# XHSC_HC32L021 register map
Vendor: XHSC Co.Ltd; Series: ARMCM4; File version: 1.2
CPU: CM4 r0p0, little endian, no MPU, no FPU, 3 interrupt priority bits
Registers are 32-bit, read-write, reset 0x0 unless marked. A register's access mark holds for its fields unless they carry their own. Offsets are from the block's base; [hi:lo] are bit positions; {n}, {i} and the like mark numbered series.

## GTIM0 — desc GTIM
Base 0x40001800; alternate view of BTIM0
Same registers: GTIM1 0x40001C00 (alternate view of BTIM3)
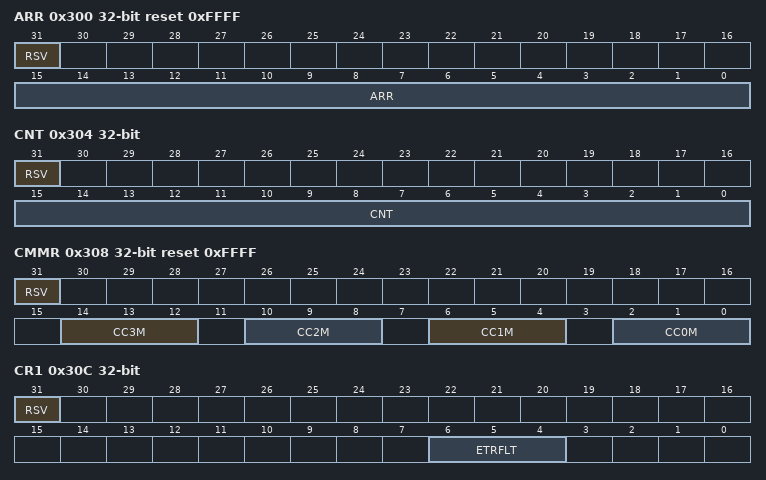
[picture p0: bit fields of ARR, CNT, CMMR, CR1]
0x300 ARR reset 0xFFFF (reset mask 0xFFFF)
  [31] RSV, [15:0] ARR
0x304 CNT (reset mask 0xFFFF)
  [31] RSV, [15:0] CNT
0x308 CMMR reset 0xFFFF (reset mask 0x7777)
  [31] RSV, [4n+2:4n] CC{n}M (n=0..3)
0x30C CR1 (reset mask 0x70)
  [31] RSV, [6:4] ETRFLT
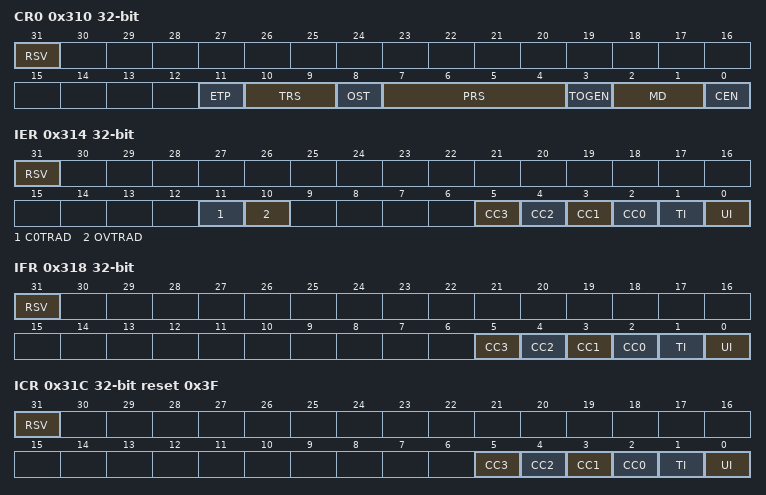
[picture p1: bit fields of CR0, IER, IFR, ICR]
0x310 CR0 (reset mask 0xFFF)
  [31] RSV, [11] ETP, [10:9] TRS, [8] OST, [7:4] PRS, [3] TOGEN, [2:1] MD, [0] CEN
0x314 IER (reset mask 0xFFF)
  [31] RSV, [11] C0TRAD, [10] OVTRAD, [n+2] CC{n} (n=0..3), [1] TI, [0] UI
0x318 IFR (reset mask 0x3F)
  [31] RSV, [n+2] CC{n} (n=0..3), [1] TI, [0] UI
0x31C ICR reset 0x3F (reset mask 0x3F)
  [31] RSV, [n+2] CC{n} (n=0..3), [1] TI, [0] UI
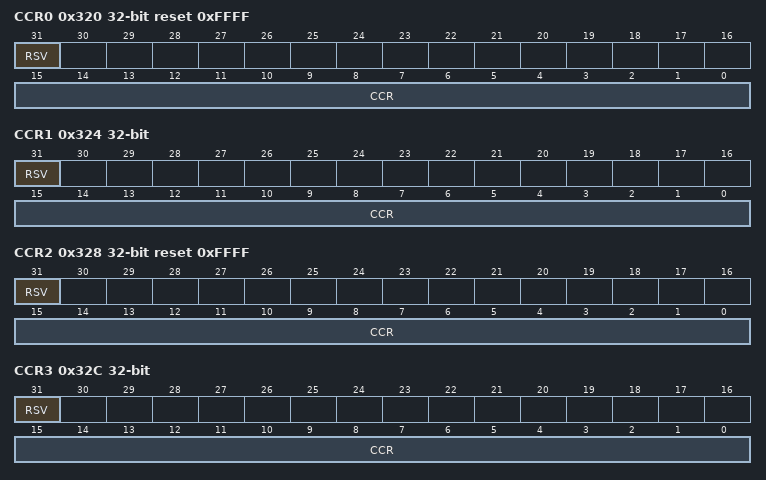
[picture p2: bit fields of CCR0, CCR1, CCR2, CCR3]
0x320 CCR0 reset 0xFFFF (reset mask 0xFFFF)
  [31] RSV, [15:0] CCR
0x324 CCR1 (reset mask 0xFFFF)
  [31] RSV, [15:0] CCR
0x328 CCR2 reset 0xFFFF (reset mask 0xFFFF)
  [31] RSV, [15:0] CCR
0x32C CCR3 (reset mask 0xFFFF)
  [31] RSV, [15:0] CCR

## HSI2C0 — desc HSI2C
Base 0x4000BC00
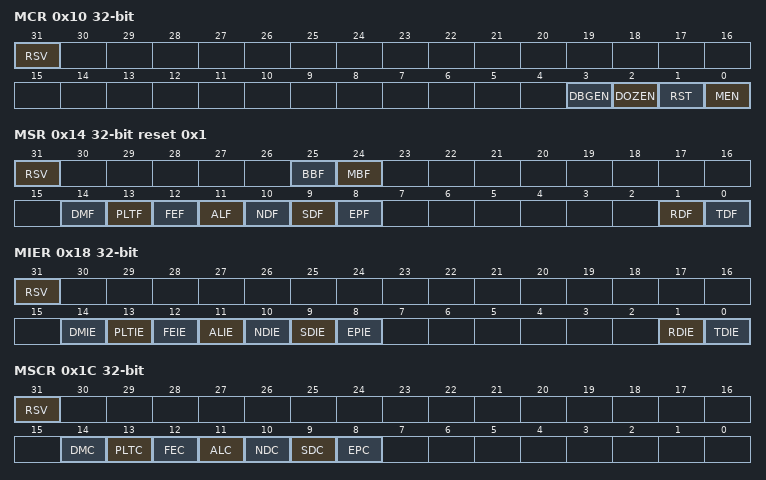
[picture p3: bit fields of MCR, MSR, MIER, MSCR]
0x10 MCR (reset mask 0xF)
  [31] RSV, [3] DBGEN, [2] DOZEN, [1] RST, [0] MEN
0x14 MSR ro reset 0x1 (reset mask 0x0)
  [31] RSV rw, [25] BBF, [24] MBF, [14] DMF, [13] PLTF, [12] FEF, [11] ALF, [10] NDF, [9] SDF, [8] EPF, [1] RDF, [0] TDF
0x18 MIER (reset mask 0x7F03)
  [31] RSV, [14] DMIE, [13] PLTIE, [12] FEIE, [11] ALIE, [10] NDIE, [9] SDIE, [8] EPIE, [1] RDIE, [0] TDIE
0x1C MSCR wo (reset mask 0x7F00)
  [31] RSV, [14] DMC, [13] PLTC, [12] FEC, [11] ALC, [10] NDC, [9] SDC, [8] EPC
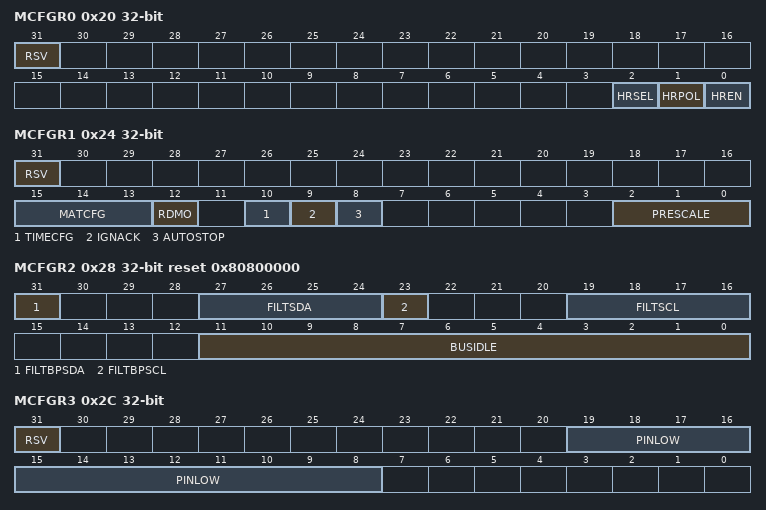
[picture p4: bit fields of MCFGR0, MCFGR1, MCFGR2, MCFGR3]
0x20 MCFGR0 (reset mask 0x307)
  [31] RSV, [2] HRSEL, [1] HRPOL, [0] HREN
0x24 MCFGR1 (reset mask 0xF707)
  [31] RSV, [15:13] MATCFG, [12] RDMO, [10] TIMECFG, [9] IGNACK, [8] AUTOSTOP, [2:0] PRESCALE
0x28 MCFGR2 reset 0x80800000
  [31] FILTBPSDA, [27:24] FILTSDA, [23] FILTBPSCL, [19:16] FILTSCL, [11:0] BUSIDLE
0x2C MCFGR3 (reset mask 0xFFF00)
  [31] RSV, [19:8] PINLOW
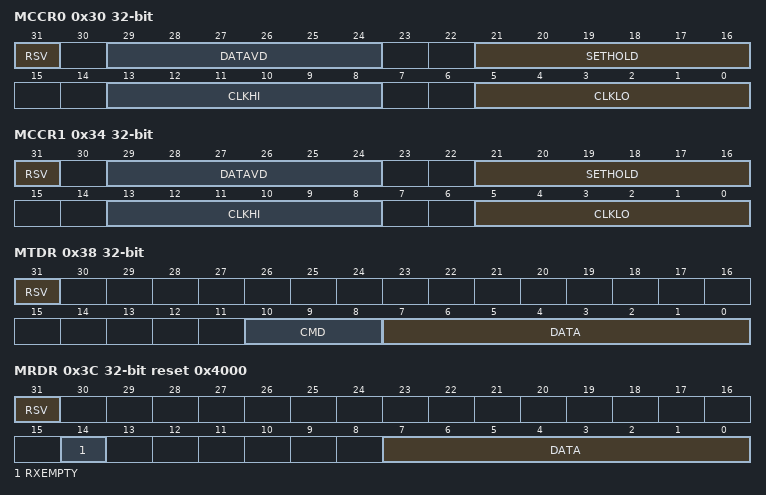
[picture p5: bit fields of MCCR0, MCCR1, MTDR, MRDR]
0x30 MCCR0 (reset mask 0x3F3F3F3F)
  [31] RSV, [29:24] DATAVD, [21:16] SETHOLD, [13:8] CLKHI, [5:0] CLKLO
0x34 MCCR1 (reset mask 0x3F3F3F3F)
  [31] RSV, [29:24] DATAVD, [21:16] SETHOLD, [13:8] CLKHI, [5:0] CLKLO
0x38 MTDR wo reset not defined
  [31] RSV, [10:8] CMD, [7:0] DATA
0x3C MRDR ro reset 0x4000 (reset mask 0x0)
  [31] RSV, [14] RXEMPTY, [7:0] DATA
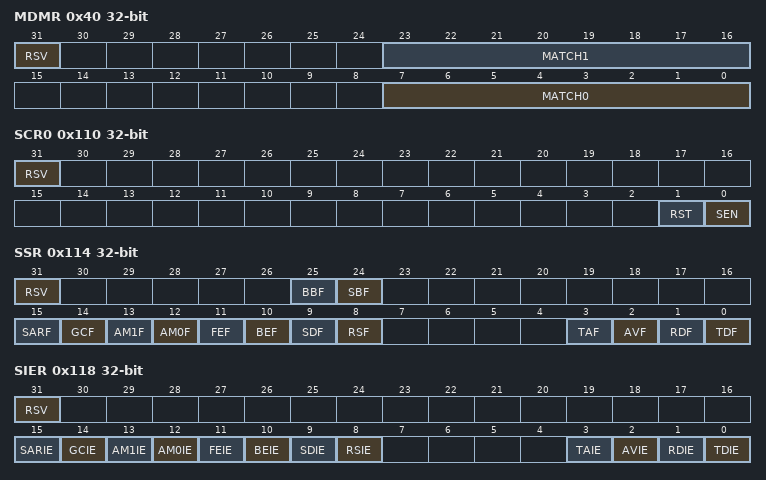
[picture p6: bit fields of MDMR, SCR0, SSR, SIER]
0x40 MDMR (reset mask 0xFF00FF)
  [31] RSV, [23:16] MATCH1, [7:0] MATCH0
0x110 SCR0 (reset mask 0x3)
  [31] RSV ro, [1] RST, [0] SEN
0x114 SSR ro reset not defined
  [31] RSV, [25] BBF, [24] SBF, [15] SARF, [14] GCF, [13] AM1F, [12] AM0F, [11] FEF, [10] BEF, [9] SDF, [8] RSF, [3] TAF, [2] AVF, [1] RDF, [0] TDF
0x118 SIER (reset mask 0xFF0F)
  [31] RSV, [15] SARIE, [14] GCIE, [13] AM1IE, [12] AM0IE, [11] FEIE, [10] BEIE, [9] SDIE, [8] RSIE, [3] TAIE, [2] AVIE, [1] RDIE, [0] TDIE
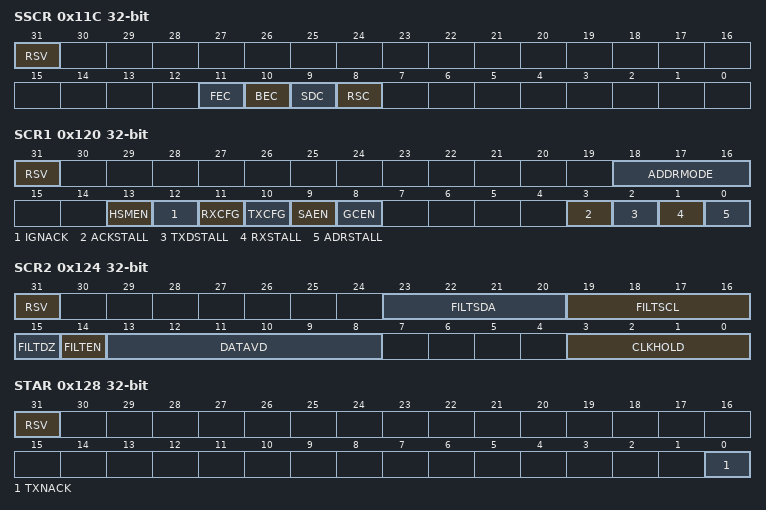
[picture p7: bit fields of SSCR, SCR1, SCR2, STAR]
0x11C SSCR wo reset not defined
  [31] RSV, [11] FEC, [10] BEC, [9] SDC, [8] RSC
0x120 SCR1 (reset mask 0x73F0F)
  [31] RSV, [18:16] ADDRMODE, [13] HSMEN, [12] IGNACK, [11] RXCFG, [10] TXCFG, [9] SAEN, [8] GCEN, [3] ACKSTALL, [2] TXDSTALL, [1] RXSTALL, [0] ADRSTALL
0x124 SCR2 (reset mask 0xFFFF0F)
  [31] RSV, [23:20] FILTSDA, [19:16] FILTSCL, [15] FILTDZ, [14] FILTEN, [13:8] DATAVD, [3:0] CLKHOLD
0x128 STAR (reset mask 0x1)
  [31] RSV, [0] TXNACK
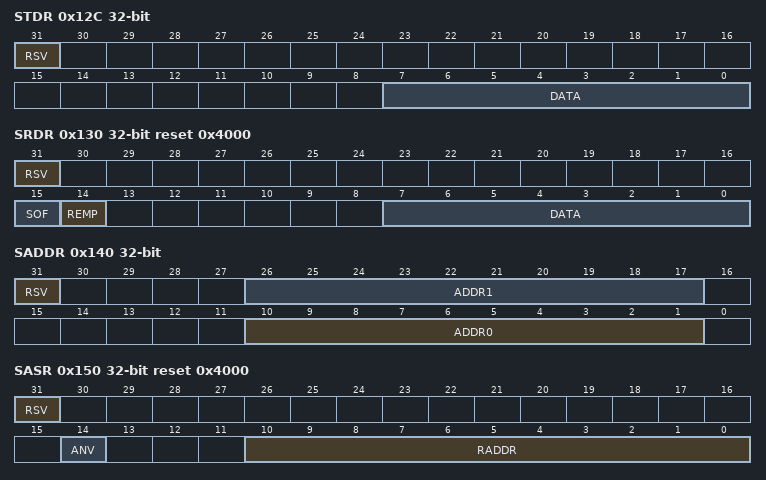
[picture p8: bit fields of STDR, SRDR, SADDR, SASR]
0x12C STDR wo reset not defined
  [31] RSV, [7:0] DATA
0x130 SRDR ro reset 0x4000 (reset mask 0x0)
  [31] RSV, [15] SOF, [14] REMP, [7:0] DATA
0x140 SADDR (reset mask 0x7FE07FE)
  [31] RSV, [26:17] ADDR1, [10:1] ADDR0
0x150 SASR ro reset 0x4000 (reset mask 0x0)
  [31] RSV, [14] ANV, [10:0] RADDR

## IWDT
Base 0x40001000
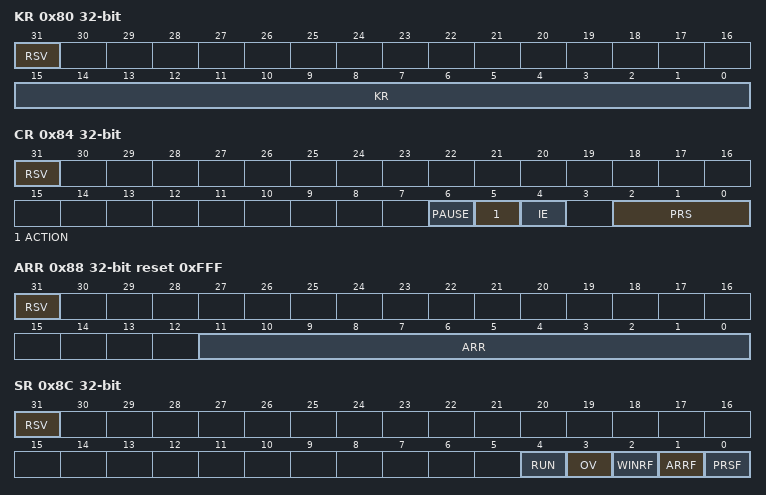
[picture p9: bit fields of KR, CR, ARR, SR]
0x80 KR wo (reset mask 0xFFFF)
  [31] RSV, [15:0] KR
0x84 CR (reset mask 0x77)
  [31] RSV, [6] PAUSE, [5] ACTION, [4] IE, [2:0] PRS
0x88 ARR reset 0xFFF (reset mask 0xFFF)
  [31] RSV, [11:0] ARR
0x8C SR (reset mask 0x1F)
  [31] RSV ro, [4] RUN ro, [3] OV ro, [2] WINRF ro, [1] ARRF ro, [0] PRSF ro
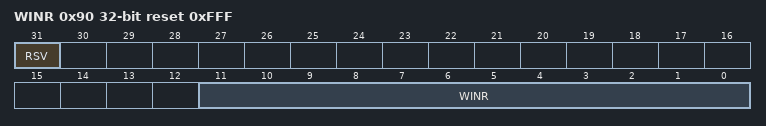
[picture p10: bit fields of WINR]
0x90 WINR reset 0xFFF (reset mask 0xFFF)
  [31] RSV, [11:0] WINR
